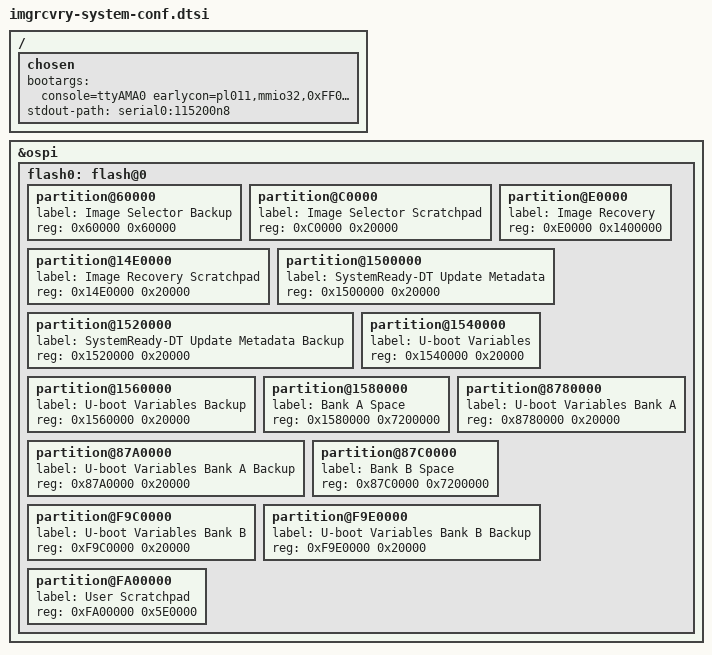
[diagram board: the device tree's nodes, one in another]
/*
* The tiny initramfs image always should launch the rootfs prompt so need to add init=/bin/sh in bootargs
*/

/ {
	chosen {
		bootargs = "console=ttyAMA0 earlycon=pl011,mmio32,0xFF000000,115200n8 root=/dev/ram0 rw debugshell=3 init=/bin/sh";
		stdout-path = "serial0:115200n8";
	};
};

&ospi {
	#address-cells = <1>;
	#size-cells = <0>;
	flash0: flash@0 {
		/delete-node/ partition@0;
		/delete-node/ partition@100000;
		/delete-node/ partition@600000;
		/delete-node/ partition@620000;
		/delete-node/ partition@c00000;
		partition@60000 {
                        label = "Image Selector Backup";
                        reg = <0x60000 0x60000>;
                };
                partition@C0000 {
                        label = "Image Selector Scratchpad";
                        reg = <0xC0000 0x20000>;
                };
                partition@E0000 {
                        label = "Image Recovery";
                        reg = <0xE0000 0x1400000>;
                };
                partition@14E0000 {
                        label = "Image Recovery Scratchpad";
                        reg = <0x14E0000 0x20000>;
                };
                partition@1500000 {
                        label = "SystemReady-DT Update Metadata";
                        reg = <0x1500000 0x20000>;
                };
                partition@1520000 {
                        label = "SystemReady-DT Update Metadata Backup";
                        reg = <0x1520000 0x20000>;
                };
                partition@1540000 {
                        label = "U-boot Variables";
                        reg = <0x1540000 0x20000>;
                };
                partition@1560000 {
                        label = "U-boot Variables Backup";
                        reg = <0x1560000 0x20000>;
                };
                partition@1580000 {
                        label = "Bank A Space";
                        reg = <0x1580000 0x7200000>;
                };
                partition@8780000 {
                        label = "U-boot Variables Bank A";
                        reg = <0x8780000 0x20000>;
                };
                partition@87A0000 {
                        label = "U-boot Variables Bank A Backup";
                        reg = <0x87A0000 0x20000>;
                };
                partition@87C0000 {
                        label = "Bank B Space";
                        reg = <0x87C0000 0x7200000>;
                };
                partition@F9C0000 {
                        label = "U-boot Variables Bank B";
                        reg = <0xF9C0000 0x20000>;
                };
                partition@F9E0000 {
                        label = "U-boot Variables Bank B Backup";
                        reg = <0xF9E0000 0x20000>;
                };
                partition@FA00000 {
                        label = "User Scratchpad";
                        reg = <0xFA00000 0x5E0000>;
                };
	};
};
